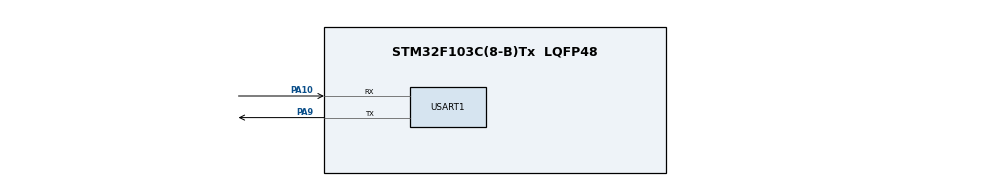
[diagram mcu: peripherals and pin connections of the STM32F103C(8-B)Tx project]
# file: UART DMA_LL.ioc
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Mcu.Family=STM32F1
Mcu.Name=STM32F103C(8-B)Tx
Mcu.Package=LQFP48
NVIC.PriorityGroup=NVIC_PRIORITYGROUP_4
NVIC.USART1_IRQn=true\:1\:0\:true\:false\:true\:true\:true\:true
PA10.Mode=Asynchronous
PA10.Signal=USART1_RX
PA13.Mode=Serial_Wire
PA13.Signal=SYS_JTMS-SWDIO
PA14.Mode=Serial_Wire
PA14.Signal=SYS_JTCK-SWCLK
PA9.Mode=Asynchronous
PA9.Signal=USART1_TX
ProjectManager.HeapSize=0x200
ProjectManager.StackSize=0x400
ProjectManager.TargetToolchain=STM32CubeIDE
RCC.AHBFreq_Value=64000000
RCC.APB1CLKDivider=RCC_HCLK_DIV2
RCC.APB1Freq_Value=32000000
RCC.APB1TimFreq_Value=64000000
RCC.APB2Freq_Value=64000000
RCC.APB2TimFreq_Value=64000000
RCC.HCLKFreq_Value=64000000
RCC.PLLMUL=RCC_PLL_MUL16
RCC.SYSCLKFreq_VALUE=64000000
RCC.SYSCLKSource=RCC_SYSCLKSOURCE_PLLCLK
RCC.USBFreq_Value=64000000
USART1.VirtualMode=VM_ASYNC
board=custom

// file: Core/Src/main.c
/* USER CODE BEGIN Header */
/**
 ******************************************************************************
 * @file           : main.c
 * @brief          : Main program body
 ******************************************************************************
 * @attention
 *
 * Copyright (c) 2024 STMicroelectronics.
 * All rights reserved.
 *
 * This software is licensed under terms that can be found in the LICENSE file
 * in the root directory of this software component.
 * If no LICENSE file comes with this software, it is provided AS-IS.
 *
 ******************************************************************************
 */
/* USER CODE END Header */
#include "main.h"

/* USER CODE BEGIN Includes */
#include "uart.h"
/* USER CODE END Includes */

UART_HandleTypeDef huart1;

void SystemClock_Config(void);
static void MX_GPIO_Init(void);
static void MX_USART1_UART_Init(void);

int main(void)
{

  /* MCU Configuration--------------------------------------------------------*/

  /* Reset of all peripherals, Initializes the Flash interface and the Systick. */
  HAL_Init();

  /* USER CODE BEGIN Init */
  configure_uart();
  configure_dma();
  /* USER CODE END Init */

  /* Configure the system clock */
  SystemClock_Config();

  /* Initialize all configured peripherals */
  MX_GPIO_Init();
  MX_USART1_UART_Init();
  /* USER CODE BEGIN 2 */
  start_transmission();
  start_receive();
  /* USER CODE END 2 */

  /* Infinite loop */
  while (1)
  {

    /* USER CODE BEGIN 3 */
	  transmit_data();
  }
  /* USER CODE END 3 */
}

void SystemClock_Config(void)
{
  LL_FLASH_SetLatency(LL_FLASH_LATENCY_2);
  while(LL_FLASH_GetLatency()!= LL_FLASH_LATENCY_2)
  {
  }
  LL_RCC_HSI_SetCalibTrimming(16);
  LL_RCC_HSI_Enable();

   /* Wait till HSI is ready */
  while(LL_RCC_HSI_IsReady() != 1)
  {

  }
  LL_RCC_PLL_ConfigDomain_SYS(LL_RCC_PLLSOURCE_HSI_DIV_2, LL_RCC_PLL_MUL_16);
  LL_RCC_PLL_Enable();

   /* Wait till PLL is ready */
  while(LL_RCC_PLL_IsReady() != 1)
  {

  }
  LL_RCC_SetAHBPrescaler(LL_RCC_SYSCLK_DIV_1);
  LL_RCC_SetAPB1Prescaler(LL_RCC_APB1_DIV_2);
  LL_RCC_SetAPB2Prescaler(LL_RCC_APB2_DIV_1);
  LL_RCC_SetSysClkSource(LL_RCC_SYS_CLKSOURCE_PLL);

   /* Wait till System clock is ready */
  while(LL_RCC_GetSysClkSource() != LL_RCC_SYS_CLKSOURCE_STATUS_PLL)
  {

  }
  LL_SetSystemCoreClock(64000000);

   /* Update the time base */
  if (HAL_InitTick (TICK_INT_PRIORITY) != HAL_OK)
  {
    Error_Handler();
  }
}

static void MX_USART1_UART_Init(void)
{

  huart1.Instance = USART1;
  huart1.Init.BaudRate = 115200;
  huart1.Init.WordLength = UART_WORDLENGTH_8B;
  huart1.Init.StopBits = UART_STOPBITS_1;
  huart1.Init.Parity = UART_PARITY_NONE;
  huart1.Init.Mode = UART_MODE_TX_RX;
  huart1.Init.HwFlowCtl = UART_HWCONTROL_NONE;
  huart1.Init.OverSampling = UART_OVERSAMPLING_16;
  if (HAL_UART_Init(&huart1) != HAL_OK)
  {
    Error_Handler();
  }

}

static void MX_GPIO_Init(void)
{

  /* GPIO Ports Clock Enable */
  LL_APB2_GRP1_EnableClock(LL_APB2_GRP1_PERIPH_GPIOA);

}

void Error_Handler(void)
{
  __disable_irq();
  while (1)
  {
  }
}

#ifdef  USE_FULL_ASSERT
/**
  * @brief  Reports the name of the source file and the source line number
  *         where the assert_param error has occurred.
  * @param  file: pointer to the source file name
  * @param  line: assert_param error line source number
  * @retval None
  */
void assert_failed(uint8_t *file, uint32_t line)
{
  /* USER CODE BEGIN 6 */
  /* User can add his own implementation to report the file name and line
     number, ex: printf("Wrong parameters value: file %s on line %d\r\n", file,
     line) */
  /* USER CODE END 6 */
}
#endif /* USE_FULL_ASSERT */
